# GD32F3x0 register map
File version: 1.0
CPU: CM4 r2p1, little endian, no MPU, no FPU, 4 interrupt priority bits
Registers are 32-bit, read-write, reset 0x0 unless marked. A register's access mark holds for its fields unless they carry their own. Offsets are from the block's base; [hi:lo] are bit positions.

## TIMER14 — General-purpose-timers
Base 0x40014000
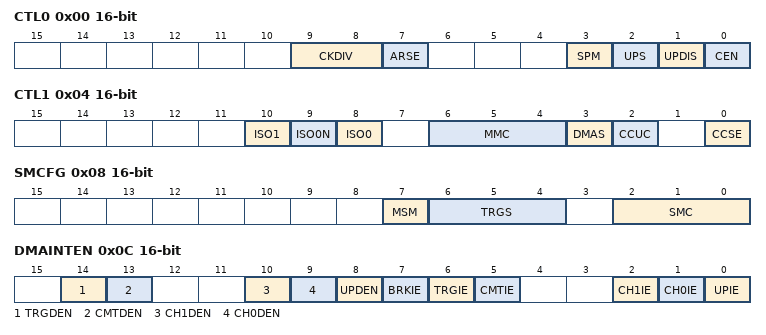
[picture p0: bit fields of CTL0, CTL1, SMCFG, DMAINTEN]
0x00 CTL0 16-bit — control register 0
  [9:8] CKDIV — Clock division
  [7] ARSE — Auto-reload preload enable
  [3] SPM — One-pulse mode
  [2] UPS — Update request source
  [1] UPDIS — Update disable
  [0] CEN — Counter enable
0x04 CTL1 16-bit — control register 1
  [10] ISO1 — Output Idle state 1
  [9] ISO0N — Output Idle state 0
  [8] ISO0 — Output Idle state 0
  [6:4] MMC — Master mode selection
  [3] DMAS — Capture/compare DMA selection
  [2] CCUC — Capture/compare control update selection
  [0] CCSE — Capture/compare preloaded control
0x08 SMCFG 16-bit — slave mode configuration register
  [7] MSM — Master/Slave mode
  [6:4] TRGS — Trigger selection
  [2:0] SMC — Slave mode selection
0x0C DMAINTEN 16-bit — DMA/Interrupt enable register
  [14] TRGDEN — Trigger DMA request enable
  [13] CMTDEN — Commutation DMA request enable
  [10] CH1DEN — Capture/Compare 1 DMA request enable
  [9] CH0DEN — Capture/Compare 0 DMA request enable
  [8] UPDEN — Update DMA request enable
  [7] BRKIE — Break interrupt enable
  [6] TRGIE — Trigger interrupt enable
  [5] CMTIE — COM interrupt enable
  [2] CH1IE — Capture/Compare 2 interrupt enable
  [1] CH0IE — Capture/Compare 1 interrupt enable
  [0] UPIE — Update interrupt enable
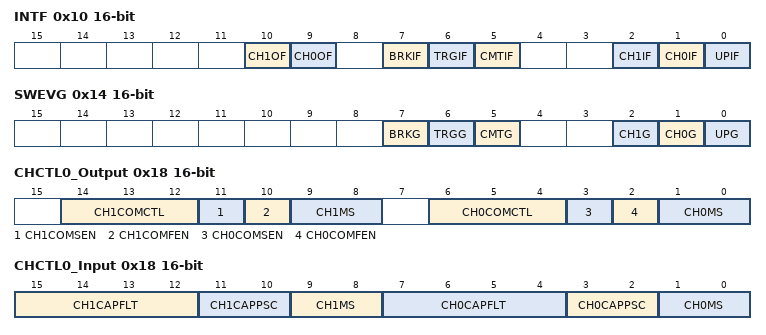
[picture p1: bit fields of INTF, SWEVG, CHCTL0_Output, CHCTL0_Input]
0x10 INTF 16-bit — interrupt flag register
  [10] CH1OF — Capture/compare 1 overcapture flag
  [9] CH0OF — Capture/Compare 0 overcapture flag
  [7] BRKIF — Break interrupt flag
  [6] TRGIF — Trigger interrupt flag
  [5] CMTIF — COM interrupt flag
  [2] CH1IF — Capture/Compare 1 interrupt flag
  [1] CH0IF — Capture/compare 0 interrupt flag
  [0] UPIF — Update interrupt flag
0x14 SWEVG 16-bit wo — event generation register
  [7] BRKG — Break generation
  [6] TRGG — Trigger generation
  [5] CMTG — Capture/Compare control update generation
  [2] CH1G — Capture/compare 1 generation
  [1] CH0G — Capture/compare 0 generation
  [0] UPG — Update generation
0x18 CHCTL0_Output 16-bit — capture/compare mode register (output mode)
  [14:12] CH1COMCTL — Output Compare 1 mode
  [11] CH1COMSEN — Output Compare 1 preload enable
  [10] CH1COMFEN — Output Compare 1 fast enable
  [9:8] CH1MS — Capture/Compare 1 selection
  [6:4] CH0COMCTL — Output Compare 0 mode
  [3] CH0COMSEN — Output Compare 0 preload enable
  [2] CH0COMFEN — Output Compare 0 fast enable
  [1:0] CH0MS — Capture/Compare 0 selection
0x18 CHCTL0_Input 16-bit (alternate view of CHCTL0_Output) — capture/compare mode register 0 (input mode)
  [15:12] CH1CAPFLT — Input capture 1 filter
  [11:10] CH1CAPPSC — Input capture 1 prescaler
  [9:8] CH1MS — Capture/Compare 1 selection
  [7:4] CH0CAPFLT — Input capture 0 filter
  [3:2] CH0CAPPSC — Input capture 0 prescaler
  [1:0] CH0MS — Capture/Compare 0 selection
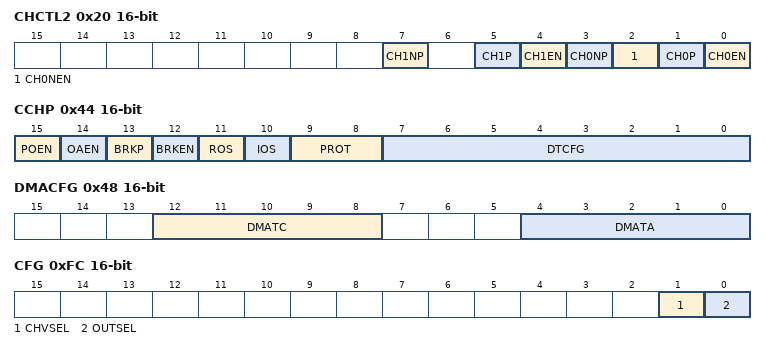
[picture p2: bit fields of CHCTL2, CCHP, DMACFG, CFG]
0x20 CHCTL2 16-bit — capture/compare enable register
  [7] CH1NP — Capture/Compare 1 output Polarity
  [5] CH1P — Capture/Compare 1 output Polarity
  [4] CH1EN — Capture/Compare 1 output enable
  [3] CH0NP — Capture/Compare 0 output Polarity
  [2] CH0NEN — Capture/Compare 0 complementary output enable
  [1] CH0P — Capture/Compare 0 output Polarity
  [0] CH0EN — Capture/Compare 0 output enable
0x24 CNT 16-bit — counter
  [15:0] CNT — counter value
0x28 PSC 16-bit — prescaler
  [15:0] PSC — Prescaler value
0x2C CAR — auto-reload register
  [15:0] CARL — Auto-reload value
0x30 CREP 16-bit — repetition counter register
  [7:0] CREP — Repetition counter value
0x34 CH0CV 16-bit — capture/compare register 0
  [15:0] CH0VAL — Capture/Compare 0 value
0x38 CH1CV 16-bit — capture/compare register 1
  [15:0] CH1VAL — Capture/Compare 1 value
0x44 CCHP 16-bit — break and dead-time register
  [15] POEN — Main output enable
  [14] OAEN — Automatic output enable
  [13] BRKP — Break polarity
  [12] BRKEN — Break enable
  [11] ROS — Off-state selection for Run mode
  [10] IOS — Off-state selection for Idle mode
  [9:8] PROT — complementary register protect control
  [7:0] DTCFG — Dead-time generator configure
0x48 DMACFG 16-bit — DMA configuration register
  [12:8] DMATC — DMA burst length
  [4:0] DMATA — DMA base address
0x4C DMATB 16-bit — DMA transfer buffer register
  [15:0] DMATB — DMA register for burst accesses
0xFC CFG 16-bit — configuration register
  [1] CHVSEL — Write CHxVAL register selection
  [0] OUTSEL — The output value selection
